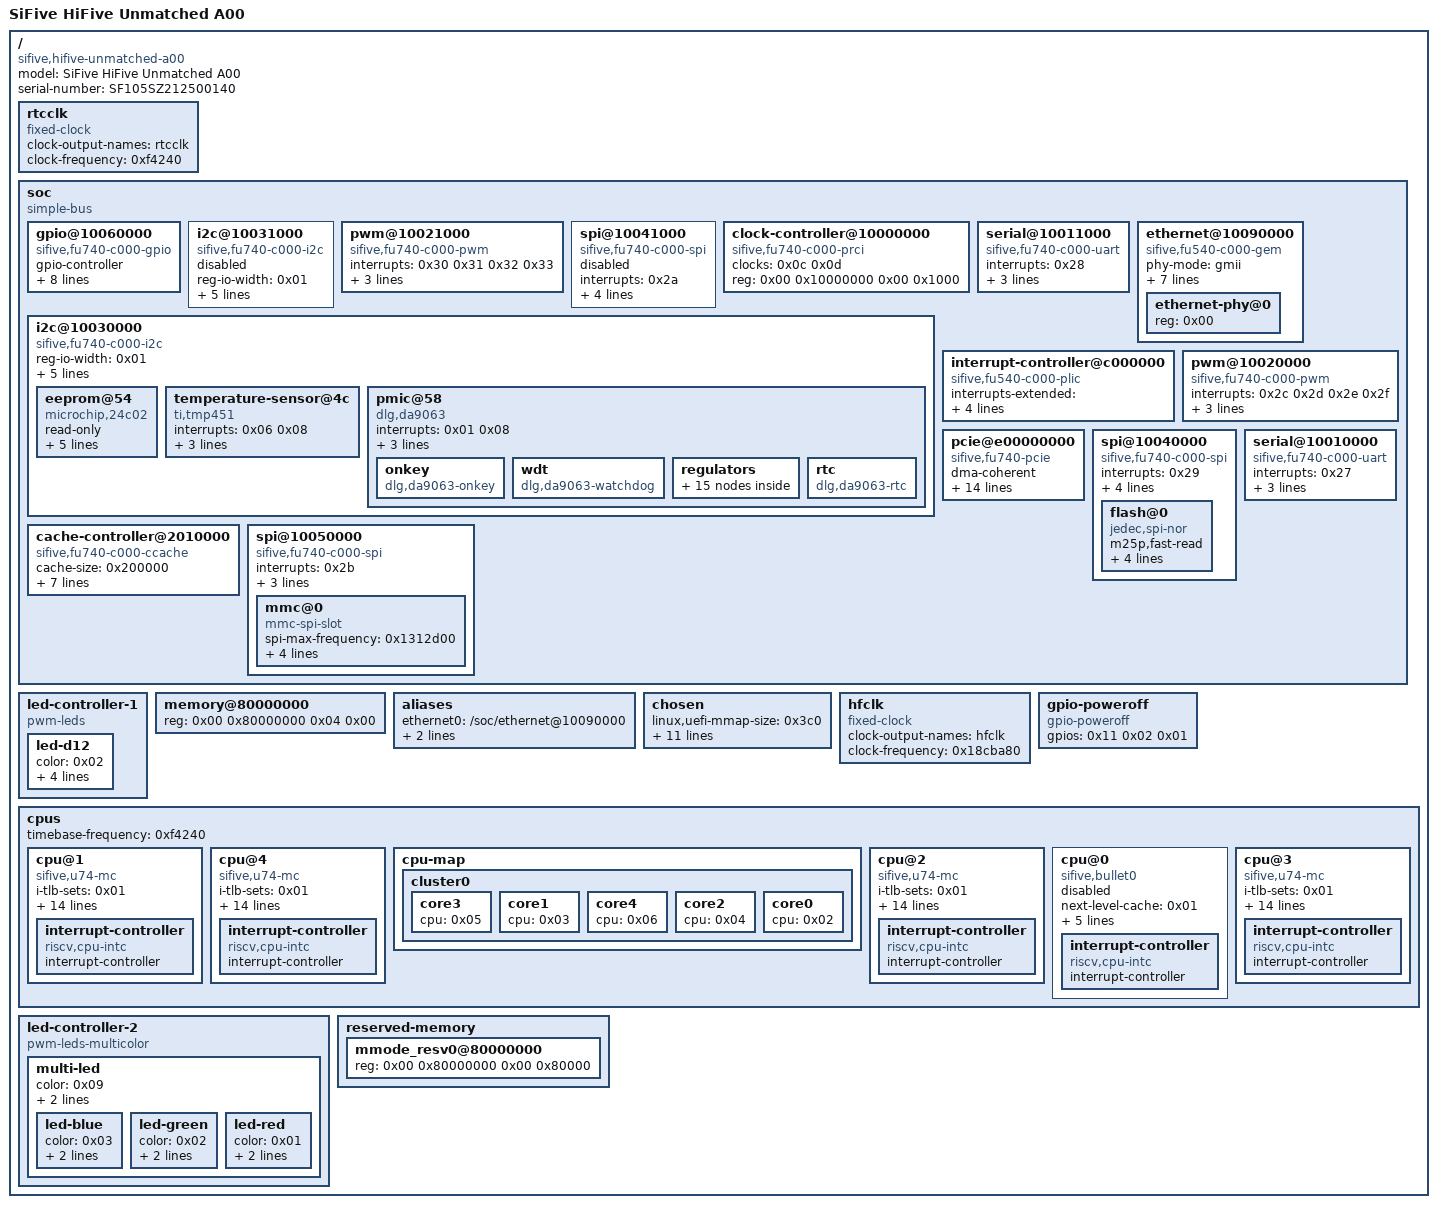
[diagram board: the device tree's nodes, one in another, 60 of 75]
/dts-v1/;

/ {
    #address-cells = <0x02>;
    model = "SiFive HiFive Unmatched A00";
    serial-number = "SF105SZ212500140";
    #size-cells = <0x02>;
    compatible = "sifive,hifive-unmatched-a00\0sifive,fu740-c000\0sifive,fu740";

    rtcclk {
        clock-output-names = "rtcclk";
        #clock-cells = <0x00>;
        clock-frequency = <0xf4240>;
        compatible = "fixed-clock";
        phandle = <0x0d>;
    };

    soc {
        #address-cells = <0x02>;
        #size-cells = <0x02>;
        compatible = "simple-bus";
        ranges;

        gpio@10060000 {
            gpio-controller;
            gpio-line-names = "J29.1\0PMICNTB\0PMICSHDN\0J8.1\0J8.3\0PCIe_PWREN\0THERM\0UBRDG_RSTN\0PCIe_PERSTN\0ULPI_RSTN\0J8.2\0UHUB_RSTN\0GEMGXL_RST\0J8.4\0EN_VDD_SD\0SD_CD";
            interrupts = <0x17 0x18 0x19 0x1a 0x1b 0x1c 0x1d 0x1e 0x1f 0x20 0x21 0x22 0x23 0x24 0x25 0x26>;
            clocks = <0x0f 0x07>;
            interrupt-parent = <0x0e>;
            compatible = "sifive,fu740-c000-gpio\0sifive,gpio0";
            #interrupt-cells = <0x02>;
            status = "okay";
            reg = <0x00 0x10060000 0x00 0x1000>;
            phandle = <0x11>;
            #gpio-cells = <0x02>;
            interrupt-controller;
        };

        i2c@10031000 {
            reg-io-width = <0x01>;
            #address-cells = <0x01>;
            interrupts = <0x35>;
            clocks = <0x0f 0x07>;
            #size-cells = <0x00>;
            interrupt-parent = <0x0e>;
            compatible = "sifive,fu740-c000-i2c\0sifive,i2c0";
            status = "disabled";
            reg = <0x00 0x10031000 0x00 0x1000>;
            reg-shift = <0x02>;
        };

        pwm@10021000 {
            interrupts = <0x30 0x31 0x32 0x33>;
            clocks = <0x0f 0x07>;
            interrupt-parent = <0x0e>;
            #pwm-cells = <0x03>;
            compatible = "sifive,fu740-c000-pwm\0sifive,pwm0";
            status = "okay";
            reg = <0x00 0x10021000 0x00 0x1000>;
        };

        spi@10041000 {
            #address-cells = <0x01>;
            interrupts = <0x2a>;
            clocks = <0x0f 0x07>;
            #size-cells = <0x00>;
            interrupt-parent = <0x0e>;
            compatible = "sifive,fu740-c000-spi\0sifive,spi0";
            status = "disabled";
            reg = <0x00 0x10041000 0x00 0x1000 0x00 0x30000000 0x00 0x10000000>;
        };

        clock-controller@10000000 {
            #reset-cells = <0x01>;
            clocks = <0x0c 0x0d>;
            #clock-cells = <0x01>;
            compatible = "sifive,fu740-c000-prci";
            reg = <0x00 0x10000000 0x00 0x1000>;
            phandle = <0x0f>;
        };

        serial@10011000 {
            interrupts = <0x28>;
            clocks = <0x0f 0x07>;
            interrupt-parent = <0x0e>;
            compatible = "sifive,fu740-c000-uart\0sifive,uart0";
            status = "okay";
            reg = <0x00 0x10011000 0x00 0x1000>;
        };

        ethernet@10090000 {
            #address-cells = <0x01>;
            phy-mode = "gmii";
            clock-names = "pclk\0hclk";
            local-mac-address = [70 b3 d5 92 fa ea];
            interrupts = <0x37>;
            clocks = <0x0f 0x02 0x0f 0x02>;
            #size-cells = <0x00>;
            interrupt-parent = <0x0e>;
            compatible = "sifive,fu540-c000-gem";
            status = "okay";
            reg = <0x00 0x10090000 0x00 0x2000 0x00 0x100a0000 0x00 0x1000>;
            phy-handle = <0x12>;

            ethernet-phy@0 {
                reg = <0x00>;
                phandle = <0x12>;
            };
        };

        i2c@10030000 {
            reg-io-width = <0x01>;
            #address-cells = <0x01>;
            interrupts = <0x34>;
            clocks = <0x0f 0x07>;
            #size-cells = <0x00>;
            interrupt-parent = <0x0e>;
            compatible = "sifive,fu740-c000-i2c\0sifive,i2c0";
            status = "okay";
            reg = <0x00 0x10030000 0x00 0x1000>;
            reg-shift = <0x02>;

            eeprom@54 {
                read-only;
                label = "board-id";
                compatible = "microchip,24c02\0atmel,24c02";
                size = <0x100>;
                pagesize = <0x10>;
                reg = <0x54>;
                vcc-supply = <0x10>;
            };

            temperature-sensor@4c {
                interrupts = <0x06 0x08>;
                interrupt-parent = <0x11>;
                compatible = "ti,tmp451";
                reg = <0x4c>;
                vcc-supply = <0x10>;
            };

            pmic@58 {
                interrupts = <0x01 0x08>;
                interrupt-parent = <0x11>;
                compatible = "dlg,da9063";
                reg = <0x58>;
                interrupt-controller;

                onkey {
                    compatible = "dlg,da9063-onkey";
                };

                wdt {
                    compatible = "dlg,da9063-watchdog";
                };

                regulators {

                    bpro {
                        regulator-max-microvolt = <0x1b7740>;
                        regulator-min-microamp = <0x249f00>;
                        regulator-always-on;
                        regulator-min-microvolt = <0x1b7740>;
                        phandle = <0x10>;
                        regulator-max-microamp = <0x249f00>;
                    };

                    ldo8 {
                        regulator-max-microvolt = <0x325aa0>;
                        regulator-always-on;
                        regulator-min-microvolt = <0x325aa0>;
                    };

                    ldo6 {
                        regulator-max-microvolt = <0x1b7740>;
                        regulator-always-on;
                        regulator-min-microvolt = <0x1b7740>;
                    };

                    bmem-bio-merged {
                        regulator-max-microvolt = <0x124f80>;
                        regulator-min-microamp = <0x2dc6c0>;
                        regulator-always-on;
                        regulator-min-microvolt = <0x124f80>;
                        regulator-max-microamp = <0x2dc6c0>;
                    };

                    ldo10 {
                        regulator-max-microvolt = <0xf4240>;
                        regulator-always-on;
                        regulator-min-microvolt = <0xf4240>;
                    };

                    ldo4 {
                        regulator-max-microvolt = <0x2625a0>;
                        regulator-always-on;
                        regulator-min-microvolt = <0x2625a0>;
                    };

                    bperi {
                        regulator-max-microvolt = <0x102ca0>;
                        regulator-min-microamp = <0x16e360>;
                        regulator-always-on;
                        regulator-min-microvolt = <0x102ca0>;
                        regulator-max-microamp = <0x16e360>;
                    };

                    bcores-merged {
                        regulator-max-microvolt = <0x100590>;
                        regulator-min-microamp = "\0I>";
                        regulator-always-on;
                        regulator-min-microvolt = <0x100590>;
                        regulator-max-microamp = "\0I>";
                    };

                    ldo2 {
                        regulator-max-microvolt = <0x1b7740>;
                        regulator-always-on;
                        regulator-min-microvolt = <0x1b7740>;
                    };

                    ldo9 {
                        regulator-max-microvolt = <0x100590>;
                        regulator-always-on;
                        regulator-min-microvolt = <0x100590>;
                    };

                    ldo7 {
                        regulator-max-microvolt = <0x325aa0>;
                        regulator-always-on;
                        regulator-min-microvolt = <0x325aa0>;
                    };

                    ldo11 {
                        regulator-max-microvolt = <0x2625a0>;
                        regulator-always-on;
                        regulator-min-microvolt = <0x2625a0>;
                    };

                    ldo5 {
                        regulator-max-microvolt = <0x325aa0>;
                        regulator-always-on;
                        regulator-min-microvolt = <0x325aa0>;
                    };

                    ldo3 {
                        regulator-max-microvolt = <0x325aa0>;
                        regulator-always-on;
                        regulator-min-microvolt = <0x325aa0>;
                    };

                    ldo1 {
                        regulator-max-microvolt = <0x1b7740>;
                        regulator-always-on;
                        regulator-min-microvolt = <0x1b7740>;
                    };
                };

                rtc {
                    compatible = "dlg,da9063-rtc";
                };
            };
        };

        interrupt-controller@c000000 {
            #address-cells = <0x00>;
            interrupts-extended = <0x07 0xffffffff 0x08 0xffffffff 0x08 0x09 0x09 0xffffffff 0x09 0x09 0x0a 0xffffffff 0x0a 0x09 0x0b 0xffffffff 0x0b 0x09>;
            compatible = "sifive,fu540-c000-plic\0sifive,plic-1.0.0";
            #interrupt-cells = <0x01>;
            reg = <0x00 0xc000000 0x00 0x4000000>;
            phandle = <0x0e>;
            riscv,ndev = <0x45>;
            interrupt-controller;
        };

        pwm@10020000 {
            interrupts = <0x2c 0x2d 0x2e 0x2f>;
            clocks = <0x0f 0x07>;
            interrupt-parent = <0x0e>;
            #pwm-cells = <0x03>;
            compatible = "sifive,fu740-c000-pwm\0sifive,pwm0";
            status = "okay";
            reg = <0x00 0x10020000 0x00 0x1000>;
            phandle = <0x13>;
        };

        pcie@e00000000 {
            #address-cells = <0x03>;
            dma-coherent;
            bus-range = <0x00 0xff>;
            clock-names = "pcie_aux";
            reg-names = "dbi\0config\0mgmt";
            resets = <0x0f 0x04>;
            interrupts = <0x38 0x39 0x3a 0x3b 0x3c 0x3d 0x3e 0x3f 0x40>;
            clocks = <0x0f 0x08>;
            interrupt-map = <0x00 0x00 0x00 0x01 0x0e 0x39 0x00 0x00 0x00 0x02 0x0e 0x3a 0x00 0x00 0x00 0x03 0x0e 0x3b 0x00 0x00 0x00 0x04 0x0e 0x3c>;
            pwren-gpios = <0x11 0x05 0x00>;
            #size-cells = <0x02>;
            interrupt-parent = <0x0e>;
            device_type = "pci";
            interrupt-map-mask = <0x00 0x00 0x00 0x07>;
            reset-gpios = <0x11 0x08 0x00>;
            num-lanes = <0x08>;
            compatible = "sifive,fu740-pcie";
            ranges = <0x81000000 0x00 0x60080000 0x00 0x60080000 0x00 0x10000 0x82000000 0x00 0x60090000 0x00 0x60090000 0x00 0xff70000 0x82000000 0x00 0x70000000 0x00 0x70000000 0x00 0x10000000 0xc3000000 0x20 0x00 0x20 0x00 0x20 0x00>;
            #interrupt-cells = <0x01>;
            status = "okay";
            interrupt-names = "msi\0inta\0intb\0intc\0intd";
            reg = <0x0e 0x00 0x00 0x80000000 0x0d 0xf0000000 0x00 0x10000000 0x00 0x100d0000 0x00 0x1000>;
        };

        spi@10040000 {
            #address-cells = <0x01>;
            interrupts = <0x29>;
            clocks = <0x0f 0x07>;
            #size-cells = <0x00>;
            interrupt-parent = <0x0e>;
            compatible = "sifive,fu740-c000-spi\0sifive,spi0";
            status = "okay";
            reg = <0x00 0x10040000 0x00 0x1000 0x00 0x20000000 0x00 0x10000000>;

            flash@0 {
                m25p,fast-read;
                spi-tx-bus-width = <0x04>;
                spi-max-frequency = <0x2faf080>;
                spi-rx-bus-width = <0x04>;
                compatible = "jedec,spi-nor";
                reg = <0x00>;
            };
        };

        cache-controller@2010000 {
            cache-size = <0x200000>;
            cache-level = <0x02>;
            cache-sets = <0x800>;
            interrupts = <0x13 0x15 0x16 0x14>;
            cache-unified;
            interrupt-parent = <0x0e>;
            compatible = "sifive,fu740-c000-ccache\0cache";
            reg = <0x00 0x2010000 0x00 0x1000>;
            phandle = <0x01>;
            cache-block-size = <0x40>;
        };

        serial@10010000 {
            interrupts = <0x27>;
            clocks = <0x0f 0x07>;
            interrupt-parent = <0x0e>;
            compatible = "sifive,fu740-c000-uart\0sifive,uart0";
            status = "okay";
            reg = <0x00 0x10010000 0x00 0x1000>;
        };

        spi@10050000 {
            #address-cells = <0x01>;
            interrupts = <0x2b>;
            clocks = <0x0f 0x07>;
            #size-cells = <0x00>;
            interrupt-parent = <0x0e>;
            compatible = "sifive,fu740-c000-spi\0sifive,spi0";
            status = "okay";
            reg = <0x00 0x10050000 0x00 0x1000>;

            mmc@0 {
                spi-max-frequency = <0x1312d00>;
                voltage-ranges = <0xce4 0xce4>;
                compatible = "mmc-spi-slot";
                disable-wp;
                reg = <0x00>;
                gpios = <0x11 0x0f 0x01>;
            };
        };
    };

    led-controller-1 {
        compatible = "pwm-leds";

        led-d12 {
            color = <0x02>;
            active-low;
            label = "d12";
            max-brightness = <0xff>;
            pwms = <0x13 0x00 0x773594 0x01>;
        };
    };

    memory@80000000 {
        device_type = "memory";
        reg = <0x00 0x80000000 0x04 0x00>;
    };

    aliases {
        ethernet0 = "/soc/ethernet@10090000";
        serial1 = "/soc/serial@10011000";
        serial0 = "/soc/serial@10010000";
    };

    chosen {
        linux,uefi-mmap-size = <0x3c0>;
        linux,initrd-end = <0x00 0xdafe42d9>;
        bootargs = "BOOT_IMAGE=/vmlinuz-5.19.0-1018-generic root=/dev/mapper/ubuntu--vg-ubuntu--lv ro";
        boot-hartid = <0x02>;
        linux,uefi-mmap-start = <0x00 0xd4049040>;
        linux,uefi-mmap-desc-size = <0x28>;
        linux,uefi-mmap-desc-ver = <0x01>;
        linux,initrd-start = <0x00 0xd424c000>;
        linux,uefi-secure-boot = <0x02>;
        linux,uefi-system-table = <0x00 0xfff5dcf8>;
        stdout-path = "serial0";
    };

    hfclk {
        clock-output-names = "hfclk";
        #clock-cells = <0x00>;
        clock-frequency = <0x18cba80>;
        compatible = "fixed-clock";
        phandle = <0x0c>;
    };

    gpio-poweroff {
        compatible = "gpio-poweroff";
        gpios = <0x11 0x02 0x01>;
    };

    cpus {
        #address-cells = <0x01>;
        #size-cells = <0x00>;
        timebase-frequency = <0xf4240>;

        cpu@1 {
            i-tlb-sets = <0x01>;
            d-cache-block-size = <0x40>;
            device_type = "cpu";
            compatible = "sifive,u74-mc\0sifive,bullet0\0riscv";
            mmu-type = "riscv,sv39";
            d-cache-size = <0x8000>;
            next-level-cache = <0x01>;
            i-cache-size = <0x8000>;
            reg = <0x01>;
            phandle = <0x03>;
            d-cache-sets = <0x40>;
            i-cache-block-size = <0x40>;
            i-cache-sets = <0x80>;
            d-tlb-size = <0x28>;
            riscv,isa = "rv64imafdc";
            tlb-split;
            i-tlb-size = <0x28>;
            d-tlb-sets = <0x01>;

            interrupt-controller {
                compatible = "riscv,cpu-intc";
                #interrupt-cells = <0x01>;
                phandle = <0x08>;
                interrupt-controller;
            };
        };

        cpu@4 {
            i-tlb-sets = <0x01>;
            d-cache-block-size = <0x40>;
            device_type = "cpu";
            compatible = "sifive,u74-mc\0sifive,bullet0\0riscv";
            mmu-type = "riscv,sv39";
            d-cache-size = <0x8000>;
            next-level-cache = <0x01>;
            i-cache-size = <0x8000>;
            reg = <0x04>;
            phandle = <0x06>;
            d-cache-sets = <0x40>;
            i-cache-block-size = <0x40>;
            i-cache-sets = <0x80>;
            d-tlb-size = <0x28>;
            riscv,isa = "rv64imafdc";
            tlb-split;
            i-tlb-size = <0x28>;
            d-tlb-sets = <0x01>;

            interrupt-controller {
                compatible = "riscv,cpu-intc";
                #interrupt-cells = <0x01>;
                phandle = <0x0b>;
                interrupt-controller;
            };
        };

        cpu-map {

            cluster0 {

                core3 {
                    cpu = <0x05>;
                };

                core1 {
                    cpu = <0x03>;
                };

                core4 {
                    cpu = <0x06>;
                };

                core2 {
                    cpu = <0x04>;
                };

                core0 {
                    cpu = <0x02>;
                };
            };
        };

        cpu@2 {
            i-tlb-sets = <0x01>;
            d-cache-block-size = <0x40>;
            device_type = "cpu";
            compatible = "sifive,u74-mc\0sifive,bullet0\0riscv";
            mmu-type = "riscv,sv39";
            d-cache-size = <0x8000>;
            next-level-cache = <0x01>;
            i-cache-size = <0x8000>;
            reg = <0x02>;
            phandle = <0x04>;
            d-cache-sets = <0x40>;
            i-cache-block-size = <0x40>;
            i-cache-sets = <0x80>;
            d-tlb-size = <0x28>;
            riscv,isa = "rv64imafdc";
            tlb-split;
            i-tlb-size = <0x28>;
            d-tlb-sets = <0x01>;

            interrupt-controller {
                compatible = "riscv,cpu-intc";
                #interrupt-cells = <0x01>;
                phandle = <0x09>;
                interrupt-controller;
            };
        };

        cpu@0 {
            device_type = "cpu";
            compatible = "sifive,bullet0\0riscv";
            status = "disabled";
            next-level-cache = <0x01>;
            i-cache-size = <0x4000>;
            reg = <0x00>;
            phandle = <0x02>;
            i-cache-block-size = <0x40>;
            i-cache-sets = <0x80>;
            riscv,isa = "rv64imac";

            interrupt-controller {
                compatible = "riscv,cpu-intc";
                #interrupt-cells = <0x01>;
                phandle = <0x07>;
                interrupt-controller;
            };
        };

        cpu@3 {
            i-tlb-sets = <0x01>;
            d-cache-block-size = <0x40>;
            device_type = "cpu";
            compatible = "sifive,u74-mc\0sifive,bullet0\0riscv";
            mmu-type = "riscv,sv39";
            d-cache-size = <0x8000>;
            next-level-cache = <0x01>;
            i-cache-size = <0x8000>;
            reg = <0x03>;
            phandle = <0x05>;
            d-cache-sets = <0x40>;
            i-cache-block-size = <0x40>;
            i-cache-sets = <0x80>;
            d-tlb-size = <0x28>;
            riscv,isa = "rv64imafdc";
            tlb-split;
            i-tlb-size = <0x28>;
            d-tlb-sets = <0x01>;

            interrupt-controller {
                compatible = "riscv,cpu-intc";
                #interrupt-cells = <0x01>;
                phandle = <0x0a>;
                interrupt-controller;
            };
        };
    };

    led-controller-2 {
        compatible = "pwm-leds-multicolor";

        multi-led {
            color = <0x09>;
            label = "d2";
            max-brightness = <0xff>;

            led-blue {
                color = <0x03>;
                active-low;
                pwms = <0x13 0x03 0x773594 0x01>;
            };

            led-green {
                color = <0x02>;
                active-low;
                pwms = <0x13 0x01 0x773594 0x01>;
            };

            led-red {
                color = <0x01>;
                active-low;
                pwms = <0x13 0x02 0x773594 0x01>;
            };
        };
    };

    reserved-memory {
        #address-cells = <0x02>;
        #size-cells = <0x02>;
        ranges;

        mmode_resv0@80000000 {
            reg = <0x00 0x80000000 0x00 0x80000>;
            phandle = <0x14>;
        };
    };
};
